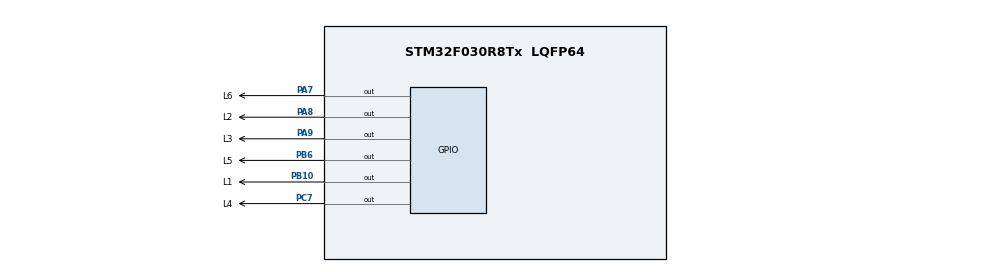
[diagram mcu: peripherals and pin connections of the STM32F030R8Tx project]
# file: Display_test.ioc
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Mcu.Family=STM32F0
Mcu.Name=STM32F030R8Tx
Mcu.Package=LQFP64
PA7.GPIO_Label=L6
PA7.Signal=GPIO_Output
PA8.GPIO_Label=L2
PA8.Signal=GPIO_Output
PA9.GPIO_Label=L3
PA9.Signal=GPIO_Output
PB10.GPIO_Label=L1
PB10.Signal=GPIO_Output
PB6.GPIO_Label=L5
PB6.Signal=GPIO_Output
PC7.GPIO_Label=L4
PC7.Signal=GPIO_Output
ProjectManager.HeapSize=0x200
ProjectManager.StackSize=0x400
ProjectManager.TargetToolchain=STM32CubeIDE
TIM3.Period=0
TIM3.Prescaler=47
VP_TIM3_VS_ClockSourceINT.Mode=Internal
board=custom

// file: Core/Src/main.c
/* USER CODE BEGIN Header */
/**
  ******************************************************************************
  * @file           : main.c
  * @brief          : Main program body
  ******************************************************************************
  * @attention
  *
  * Copyright (c) 2023 STMicroelectronics.
  * All rights reserved.
  *
  * This software is licensed under terms that can be found in the LICENSE file
  * in the root directory of this software component.
  * If no LICENSE file comes with this software, it is provided AS-IS.
  *
  ******************************************************************************
  */
/* USER CODE END Header */
#include "main.h"
#include "hd44780.c"

TIM_HandleTypeDef htim3;

void SystemClock_Config(void);
static void MX_GPIO_Init(void);
static void MX_TIM3_Init(void);

int main(void)
{

  /* MCU Configuration--------------------------------------------------------*/

  /* Reset of all peripherals, Initializes the Flash interface and the Systick. */
  HAL_Init();

  /* Configure the system clock */
  SystemClock_Config();

  /* Initialize all configured peripherals */
  MX_GPIO_Init();
  MX_TIM3_Init();
  /* USER CODE BEGIN 2 */
  lcd_init();
  lcd_clear();
  lcd_set_xyi(0, 0);
  lcd_out("Привет");
  /* USER CODE END 2 */

  /* Infinite loop */
  while (1)
  {

  }
}

void SystemClock_Config(void)
{
  RCC_OscInitTypeDef RCC_OscInitStruct = {0};
  RCC_ClkInitTypeDef RCC_ClkInitStruct = {0};

  /** Initializes the RCC Oscillators according to the specified parameters
  * in the RCC_OscInitTypeDef structure.
  */
  RCC_OscInitStruct.OscillatorType = RCC_OSCILLATORTYPE_HSI;
  RCC_OscInitStruct.HSIState = RCC_HSI_ON;
  RCC_OscInitStruct.HSICalibrationValue = RCC_HSICALIBRATION_DEFAULT;
  RCC_OscInitStruct.PLL.PLLState = RCC_PLL_NONE;
  if (HAL_RCC_OscConfig(&RCC_OscInitStruct) != HAL_OK)
  {
    Error_Handler();
  }

  /** Initializes the CPU, AHB and APB buses clocks
  */
  RCC_ClkInitStruct.ClockType = RCC_CLOCKTYPE_HCLK|RCC_CLOCKTYPE_SYSCLK
                              |RCC_CLOCKTYPE_PCLK1;
  RCC_ClkInitStruct.SYSCLKSource = RCC_SYSCLKSOURCE_HSI;
  RCC_ClkInitStruct.AHBCLKDivider = RCC_SYSCLK_DIV1;
  RCC_ClkInitStruct.APB1CLKDivider = RCC_HCLK_DIV1;

  if (HAL_RCC_ClockConfig(&RCC_ClkInitStruct, FLASH_LATENCY_0) != HAL_OK)
  {
    Error_Handler();
  }
}

static void MX_TIM3_Init(void)
{

  TIM_ClockConfigTypeDef sClockSourceConfig = {0};
  TIM_MasterConfigTypeDef sMasterConfig = {0};

  htim3.Instance = TIM3;
  htim3.Init.Prescaler = 47;
  htim3.Init.CounterMode = TIM_COUNTERMODE_UP;
  htim3.Init.Period = 0;
  htim3.Init.ClockDivision = TIM_CLOCKDIVISION_DIV1;
  htim3.Init.AutoReloadPreload = TIM_AUTORELOAD_PRELOAD_DISABLE;
  if (HAL_TIM_Base_Init(&htim3) != HAL_OK)
  {
    Error_Handler();
  }
  sClockSourceConfig.ClockSource = TIM_CLOCKSOURCE_INTERNAL;
  if (HAL_TIM_ConfigClockSource(&htim3, &sClockSourceConfig) != HAL_OK)
  {
    Error_Handler();
  }
  sMasterConfig.MasterOutputTrigger = TIM_TRGO_RESET;
  sMasterConfig.MasterSlaveMode = TIM_MASTERSLAVEMODE_DISABLE;
  if (HAL_TIMEx_MasterConfigSynchronization(&htim3, &sMasterConfig) != HAL_OK)
  {
    Error_Handler();
  }

}

static void MX_GPIO_Init(void)
{
  GPIO_InitTypeDef GPIO_InitStruct = {0};

  /* GPIO Ports Clock Enable */
  __HAL_RCC_GPIOA_CLK_ENABLE();
  __HAL_RCC_GPIOB_CLK_ENABLE();
  __HAL_RCC_GPIOC_CLK_ENABLE();

  /*Configure GPIO pin Output Level */
  HAL_GPIO_WritePin(GPIOA, L1_Pin|L2_Pin, GPIO_PIN_RESET);

  /*Configure GPIO pin Output Level */
  HAL_GPIO_WritePin(GPIOB, L3_Pin|L4_Pin|L5_Pin|L6_Pin, GPIO_PIN_RESET);

  /*Configure GPIO pins : L6_Pin L2_Pin L3_Pin */
  GPIO_InitStruct.Pin = L1_Pin|L2_Pin;
  GPIO_InitStruct.Mode = GPIO_MODE_OUTPUT_PP;
  GPIO_InitStruct.Pull = GPIO_NOPULL;
  GPIO_InitStruct.Speed = GPIO_SPEED_FREQ_LOW;
  HAL_GPIO_Init(GPIOA, &GPIO_InitStruct);

  /*Configure GPIO pins : L1_Pin L5_Pin */
  GPIO_InitStruct.Pin = L3_Pin|L4_Pin|L5_Pin|L6_Pin;
  GPIO_InitStruct.Mode = GPIO_MODE_OUTPUT_PP;
  GPIO_InitStruct.Pull = GPIO_NOPULL;
  GPIO_InitStruct.Speed = GPIO_SPEED_FREQ_LOW;
  HAL_GPIO_Init(GPIOB, &GPIO_InitStruct);

}

void Error_Handler(void)
{
  __disable_irq();
  while (1)
  {
  }
}
